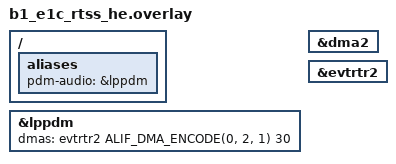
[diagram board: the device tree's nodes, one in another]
/* Copyright (C) 2024 Alif Semiconductor - All Rights Reserved.
 * Use, distribution and modification of this code is permitted under the
 * terms stated in the Alif Semiconductor Software License Agreement
 *
 * You should have received a copy of the Alif Semiconductor Software
 * License Agreement with this file. If not, please write to:
 * contact@alifsemi.com, or visit: https://alifsemi.com/license
 *
 */
#include <zephyr/dt-bindings/dma/alif_dma_event_router.h>
/* Set to 1 for DMA mode, 0 for normal interrupt mode */
#define USE_DMA 1
/ {
	aliases {
		pdm-audio = &lppdm;
	};
};
#if USE_DMA
&lppdm {
	status = "okay";
	dmas = <&evtrtr2 ALIF_DMA_ENCODE(0, 2, 1) 30>;
	dma-names = "pdm_dma_1";
};
&dma2 {
	status = "okay";
};
&evtrtr2 {
	status = "okay";
};
#else
/* Normal interrupt mode */
&lppdm {
	status = "okay";
};
#endif
